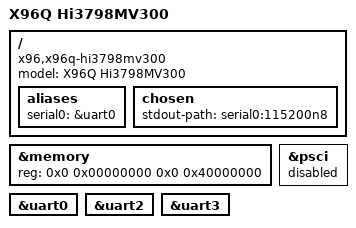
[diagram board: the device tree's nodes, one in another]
// SPDX-License-Identifier: BSD-3-Clause
/*
 * Copyright (C) 2026 Danila Tikhonov <danila@jiaxyga.com>
 */

/dts-v1/;

#include "hi3798mv300.dtsi"

/ {
	model = "X96Q Hi3798MV300";
	compatible = "x96,x96q-hi3798mv300",
		     "hisilicon,hi3798mv300";

	aliases {
		serial0 = &uart0;
	};

	chosen {
		stdout-path = "serial0:115200n8";
	};
};

&memory {
	reg = <0x0 0x00000000 0x0 0x40000000>;
};

&psci {
	status = "disabled";
};

&uart0 {
	status = "okay";
};

&uart2 {
	status = "okay";
};

&uart3 {
	status = "okay";
};
